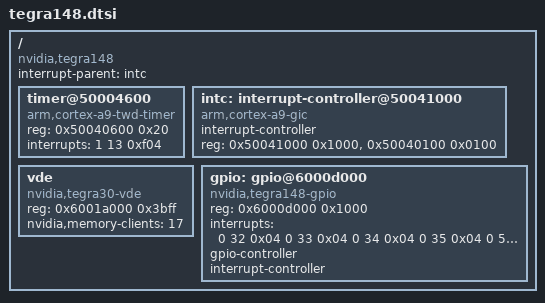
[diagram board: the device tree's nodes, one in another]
/include/ "skeleton.dtsi"

/ {
	compatible = "nvidia,tegra148";
        interrupt-parent = <&intc>;


	timer@50004600 {
		compatible = "arm,cortex-a9-twd-timer";
		reg = <0x50040600 0x20>;
		interrupts = <1 13 0xf04>;
	};

        intc: interrupt-controller@50041000 {
                compatible = "arm,cortex-a9-gic";
                interrupt-controller;
                #interrupt-cells = <3>;
                reg = <0x50041000 0x1000>,
                      <0x50040100 0x0100>;
        };

	vde {
		reg = <0x6001a000 0x3bff>;
		compatible = "nvidia,tegra30-vde";
		nvidia,memory-clients = <17>;
	};

	gpio: gpio@6000d000 {
		compatible = "nvidia,tegra148-gpio", "nvidia,tegra30-gpio";
		reg = <0x6000d000 0x1000>;
		interrupts = <0 32 0x04
				0 33 0x04
				0 34 0x04
				0 35 0x04
				0 55 0x04
				0 87 0x04
				0 89 0x04
				0 125 0x04>;
		#gpio-cells = <2>;
		gpio-controller;
		#interrupt-cells = <2>;
		interrupt-controller;
	};
};
